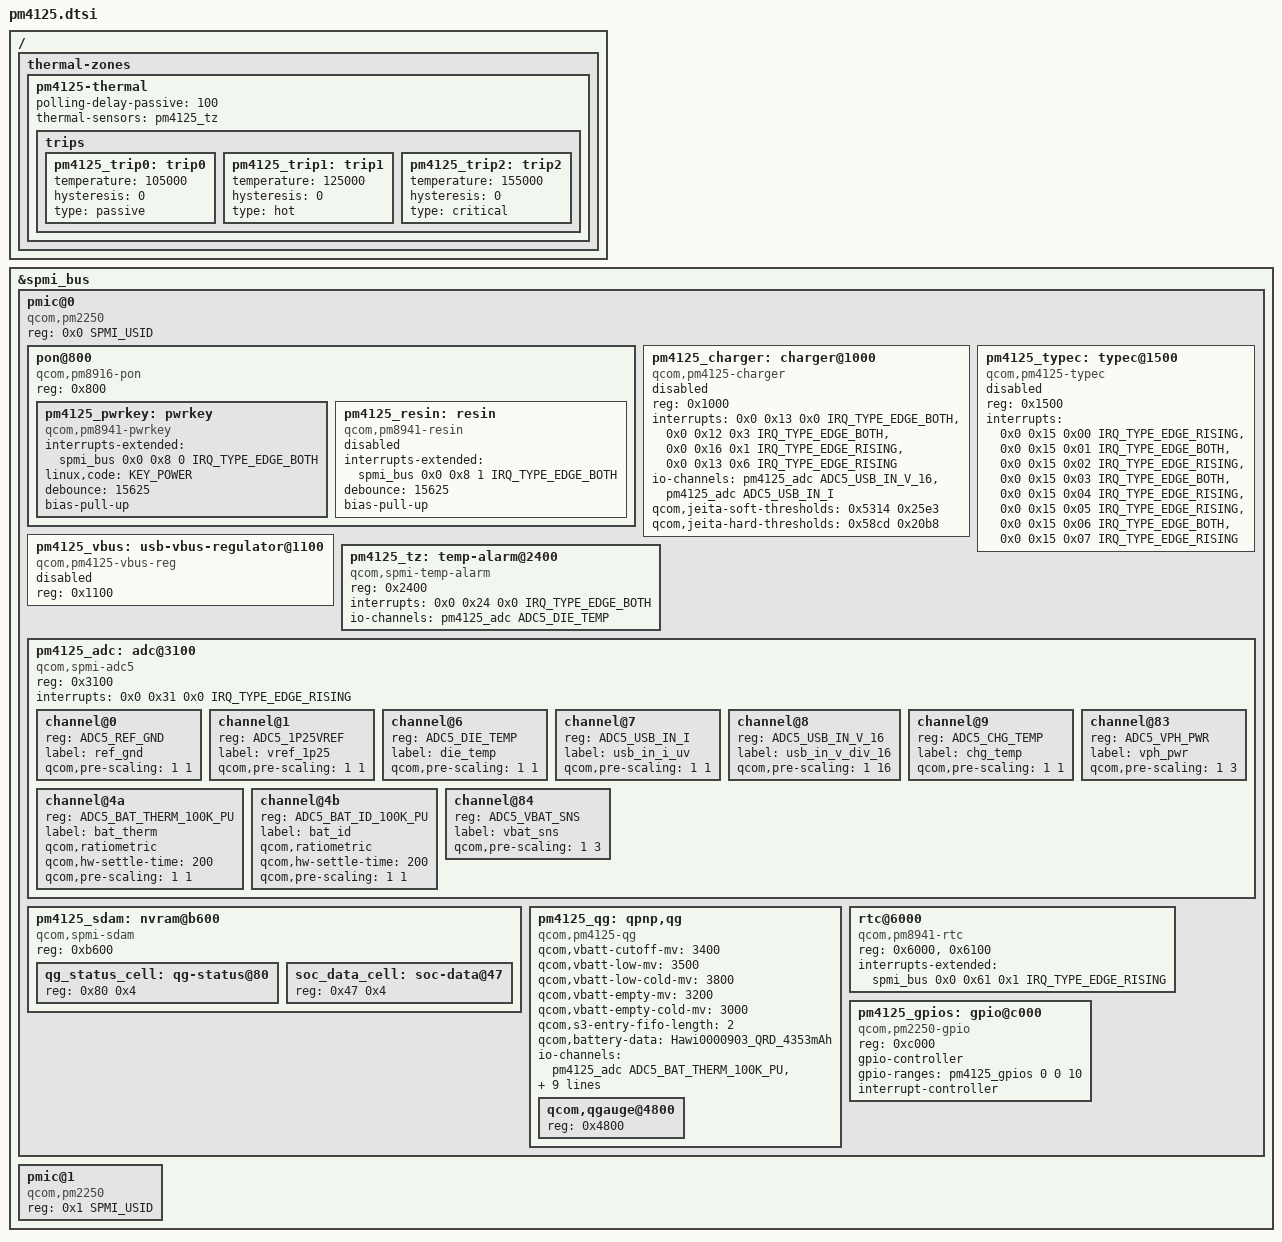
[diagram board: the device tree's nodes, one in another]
// SPDX-License-Identifier: (GPL-2.0+ OR BSD-3-Clause)
/*
 * Copyright (c) 2023, Linaro Ltd
 */

#include <dt-bindings/iio/qcom,spmi-vadc.h>
#include <dt-bindings/input/input.h>
#include <dt-bindings/interrupt-controller/irq.h>
#include <dt-bindings/spmi/spmi.h>
#include "QG_Hawi0000903_QRD_4353mAh.dtsi"

/ {
	thermal-zones {
		pm4125-thermal {
			polling-delay-passive = <100>;
			thermal-sensors = <&pm4125_tz>;

			trips {
				pm4125_trip0: trip0 {
					temperature = <105000>;
					hysteresis = <0>;
					type = "passive";
				};

				pm4125_trip1: trip1 {
					temperature = <125000>;
					hysteresis = <0>;
					type = "hot";
				};

				pm4125_trip2: trip2 {
					temperature = <155000>;
					hysteresis = <0>;
					type = "critical";
				};
			};
		};
	};
};

&spmi_bus {
	pmic@0 {
		compatible = "qcom,pm2250", "qcom,spmi-pmic";
		reg = <0x0 SPMI_USID>;
		#address-cells = <1>;
		#size-cells = <0>;

		pon@800 {
			compatible = "qcom,pm8916-pon";
			reg = <0x800>;

			pm4125_pwrkey: pwrkey {
				compatible = "qcom,pm8941-pwrkey";
				interrupts-extended = <&spmi_bus 0x0 0x8 0 IRQ_TYPE_EDGE_BOTH>;
				linux,code = <KEY_POWER>;
				debounce = <15625>;
				bias-pull-up;
			};

			pm4125_resin: resin {
				compatible = "qcom,pm8941-resin";
				interrupts-extended = <&spmi_bus 0x0 0x8 1 IRQ_TYPE_EDGE_BOTH>;
				debounce = <15625>;
				bias-pull-up;
				status = "disabled";
			};
		};

		pm4125_charger: charger@1000 {
			compatible = "qcom,pm4125-charger";
			reg = <0x1000>;

			interrupts = <0x0 0x13 0x0 IRQ_TYPE_EDGE_BOTH>,
				     <0x0 0x12 0x3 IRQ_TYPE_EDGE_BOTH>,
				     <0x0 0x16 0x1 IRQ_TYPE_EDGE_RISING>,
				     <0x0 0x13 0x6 IRQ_TYPE_EDGE_RISING>;
			interrupt-names = "usb-plugin",
					  "bat-ov",
					  "wdog-bark",
					  "usbin-icl-change";
			io-channels = <&pm4125_adc ADC5_USB_IN_V_16>,
				      <&pm4125_adc ADC5_USB_IN_I>;
			io-channel-names = "usbin_v", "usbin_i";
			qcom,jeita-soft-thresholds = <0x5314 0x25e3>; /* COOL, WARM */
			qcom,jeita-hard-thresholds = <0x58cd 0x20b8>; /* COLD, HOT */

			status = "disabled";
		};

		pm4125_vbus: usb-vbus-regulator@1100 {
			compatible = "qcom,pm4125-vbus-reg";
			reg = <0x1100>;
			status = "disabled";
		};

		pm4125_typec: typec@1500 {
			compatible = "qcom,pm4125-typec", "qcom,pmi632-typec";
			reg = <0x1500>;
			interrupts = <0x0 0x15 0x00 IRQ_TYPE_EDGE_RISING>,
				     <0x0 0x15 0x01 IRQ_TYPE_EDGE_BOTH>,
				     <0x0 0x15 0x02 IRQ_TYPE_EDGE_RISING>,
				     <0x0 0x15 0x03 IRQ_TYPE_EDGE_BOTH>,
				     <0x0 0x15 0x04 IRQ_TYPE_EDGE_RISING>,
				     <0x0 0x15 0x05 IRQ_TYPE_EDGE_RISING>,
				     <0x0 0x15 0x06 IRQ_TYPE_EDGE_BOTH>,
				     <0x0 0x15 0x07 IRQ_TYPE_EDGE_RISING>;
			interrupt-names = "or-rid-detect-change",
					  "vpd-detect",
					  "cc-state-change",
					  "vconn-oc",
					  "vbus-change",
					  "attach-detach",
					  "legacy-cable-detect",
					  "try-snk-src-detect";

			status = "disabled";
		};

		pm4125_tz: temp-alarm@2400 {
			compatible = "qcom,spmi-temp-alarm";
			reg = <0x2400>;
			interrupts = <0x0 0x24 0x0 IRQ_TYPE_EDGE_BOTH>;
			io-channels = <&pm4125_adc ADC5_DIE_TEMP>;
			io-channel-names = "thermal";
			#thermal-sensor-cells = <0>;
		};

		pm4125_adc: adc@3100 {
			compatible = "qcom,spmi-adc5";
			reg = <0x3100>;
			#address-cells = <1>;
			#size-cells = <0>;
			#io-channel-cells = <1>;
			interrupts = <0x0 0x31 0x0 IRQ_TYPE_EDGE_RISING>;

			/* Channel nodes */
			channel@0 {
				reg = <ADC5_REF_GND>;
				label = "ref_gnd";
				qcom,pre-scaling = <1 1>;
			};

			channel@1 {
				reg = <ADC5_1P25VREF>;
				label = "vref_1p25";
				qcom,pre-scaling = <1 1>;
			};

			channel@6 {
				reg = <ADC5_DIE_TEMP>;
				label = "die_temp";
				qcom,pre-scaling = <1 1>;
			};

			channel@7 {
				reg = <ADC5_USB_IN_I>;
				label = "usb_in_i_uv";
				qcom,pre-scaling = <1 1>;
			};

			channel@8 {
				reg = <ADC5_USB_IN_V_16>;
				label = "usb_in_v_div_16";
				qcom,pre-scaling = <1 16>;
			};

			channel@9 {
				reg = <ADC5_CHG_TEMP>;
				label = "chg_temp";
				qcom,pre-scaling = <1 1>;
			};

			channel@4a {
				reg = <ADC5_BAT_THERM_100K_PU>;
				label = "bat_therm";
				qcom,ratiometric;
				qcom,hw-settle-time = <200>;
				qcom,pre-scaling = <1 1>;
			};

			channel@4b {
				reg = <ADC5_BAT_ID_100K_PU>;
				label = "bat_id";
				qcom,ratiometric;
				qcom,hw-settle-time = <200>;
				qcom,pre-scaling = <1 1>;
			};

			channel@83 {
				reg = <ADC5_VPH_PWR>;
				label = "vph_pwr";
				qcom,pre-scaling = <1 3>;
			};

			channel@84 {
				reg = <ADC5_VBAT_SNS>;
				label = "vbat_sns";
				qcom,pre-scaling = <1 3>;
			};
		};

		pm4125_sdam: nvram@b600 {
			compatible = "qcom,spmi-sdam";
			reg = <0xb600>;
			#address-cells = <1>;
			#size-cells = <1>;
			ranges = <0 0xb600 0x100>;

			qg_status_cell: qg-status@80 {
				reg = <0x80 0x4>;
			};

			soc_data_cell: soc-data@47 {
				reg = <0x47 0x4>;
			};
		};

		pm4125_qg: qpnp,qg {
			compatible = "qcom,pm4125-qg";
			#address-cells = <1>;
			#size-cells = <0>;

			qcom,vbatt-cutoff-mv = <3400>;
			qcom,vbatt-low-mv = <3500>;
			qcom,vbatt-low-cold-mv = <3800>;
			qcom,vbatt-empty-mv = <3200>;
			qcom,vbatt-empty-cold-mv = <3000>;
			qcom,s3-entry-fifo-length = <2>;
			qcom,battery-data = <&Hawi0000903_QRD_4353mAh>;

			io-channels = <&pm4125_adc ADC5_BAT_THERM_100K_PU>,
				      <&pm4125_adc ADC5_BAT_ID_100K_PU>;
			io-channel-names = "batt-therm", "batt-id";

			nvmem = <&pm4125_sdam>;
			nvmem-names = "qg_sdam";
			nvmem-cells = <&qg_status_cell>, <&soc_data_cell>;
			nvmem-cell-names = "qg_status", "soc_data";

			interrupts = <0x0 0x48 0x0 IRQ_TYPE_EDGE_BOTH>,
				     <0x0 0x48 0x2 IRQ_TYPE_EDGE_RISING>,
				     <0x0 0x48 0x3 IRQ_TYPE_EDGE_RISING>,
				     <0x0 0x48 0x5 IRQ_TYPE_EDGE_RISING>;
			interrupt-names = "qg-batt-missing",
					  "qg-vbat-empty",
					  "qg-fifo-done",
					  "qg-good-ocv";

			qcom,qgauge@4800 {
				status = "okay";
				reg = <0x4800>;
			};
		};

		rtc@6000 {
			compatible = "qcom,pm8941-rtc";
			reg = <0x6000>, <0x6100>;
			reg-names = "rtc", "alarm";
			interrupts-extended = <&spmi_bus 0x0 0x61 0x1 IRQ_TYPE_EDGE_RISING>;
		};

		pm4125_gpios: gpio@c000 {
			compatible = "qcom,pm2250-gpio", "qcom,spmi-gpio";
			reg = <0xc000>;
			gpio-controller;
			gpio-ranges = <&pm4125_gpios 0 0 10>;
			#gpio-cells = <2>;
			interrupt-controller;
			#interrupt-cells = <2>;
		};
	};

	pmic@1 {
		compatible = "qcom,pm2250", "qcom,spmi-pmic";
		reg = <0x1 SPMI_USID>;
		#address-cells = <1>;
		#size-cells = <0>;
	};
};
